# PIC32MX460F256L device description
Architecture: MIPS; Family: PIC32MX; Series: PIC32MX
Registers are 32-bit, read-write, no defined reset value unless marked. A register's access mark holds for its fields unless they carry their own. Offsets are from the block's base; [hi:lo] are bit positions; {n}, {i} and the like mark numbered series.

## PORT
Instances: PORT 0x1f886000 in periph2
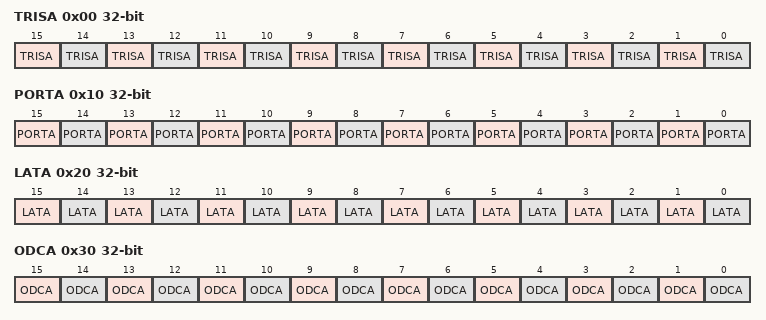
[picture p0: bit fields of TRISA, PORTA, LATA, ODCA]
0x00 TRISA
  [15] TRISA, [14] TRISA, [13] TRISA, [12] TRISA, [11] TRISA, [10] TRISA, [9] TRISA, [8] TRISA, [7] TRISA, [6] TRISA, [5] TRISA, [4] TRISA, [3] TRISA, [2] TRISA, [1] TRISA, [0] TRISA
0x10 PORTA
  [15] PORTA, [14] PORTA, [13] PORTA, [12] PORTA, [11] PORTA, [10] PORTA, [9] PORTA, [8] PORTA, [7] PORTA, [6] PORTA, [5] PORTA, [4] PORTA, [3] PORTA, [2] PORTA, [1] PORTA, [0] PORTA
0x20 LATA
  [15] LATA, [14] LATA, [13] LATA, [12] LATA, [11] LATA, [10] LATA, [9] LATA, [8] LATA, [7] LATA, [6] LATA, [5] LATA, [4] LATA, [3] LATA, [2] LATA, [1] LATA, [0] LATA
0x30 ODCA
  [15] ODCA, [14] ODCA, [13] ODCA, [12] ODCA, [11] ODCA, [10] ODCA, [9] ODCA, [8] ODCA, [7] ODCA, [6] ODCA, [5] ODCA, [4] ODCA, [3] ODCA, [2] ODCA, [1] ODCA, [0] ODCA
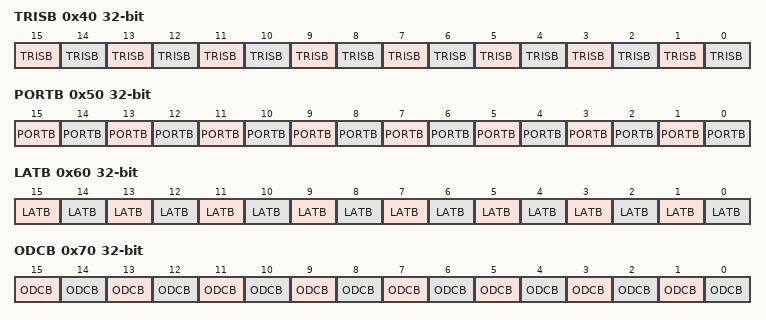
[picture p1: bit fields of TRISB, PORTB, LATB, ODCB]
0x40 TRISB
  [15] TRISB, [14] TRISB, [13] TRISB, [12] TRISB, [11] TRISB, [10] TRISB, [9] TRISB, [8] TRISB, [7] TRISB, [6] TRISB, [5] TRISB, [4] TRISB, [3] TRISB, [2] TRISB, [1] TRISB, [0] TRISB
0x50 PORTB
  [15] PORTB, [14] PORTB, [13] PORTB, [12] PORTB, [11] PORTB, [10] PORTB, [9] PORTB, [8] PORTB, [7] PORTB, [6] PORTB, [5] PORTB, [4] PORTB, [3] PORTB, [2] PORTB, [1] PORTB, [0] PORTB
0x60 LATB
  [15] LATB, [14] LATB, [13] LATB, [12] LATB, [11] LATB, [10] LATB, [9] LATB, [8] LATB, [7] LATB, [6] LATB, [5] LATB, [4] LATB, [3] LATB, [2] LATB, [1] LATB, [0] LATB
0x70 ODCB
  [15] ODCB, [14] ODCB, [13] ODCB, [12] ODCB, [11] ODCB, [10] ODCB, [9] ODCB, [8] ODCB, [7] ODCB, [6] ODCB, [5] ODCB, [4] ODCB, [3] ODCB, [2] ODCB, [1] ODCB, [0] ODCB
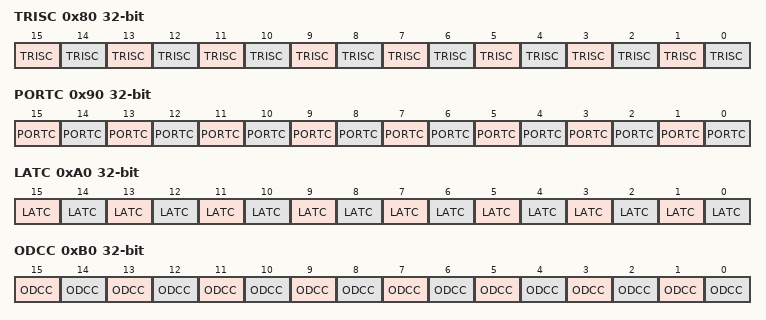
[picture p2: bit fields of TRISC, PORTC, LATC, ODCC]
0x80 TRISC
  [15] TRISC, [14] TRISC, [13] TRISC, [12] TRISC, [11] TRISC, [10] TRISC, [9] TRISC, [8] TRISC, [7] TRISC, [6] TRISC, [5] TRISC, [4] TRISC, [3] TRISC, [2] TRISC, [1] TRISC, [0] TRISC
0x90 PORTC
  [15] PORTC, [14] PORTC, [13] PORTC, [12] PORTC, [11] PORTC, [10] PORTC, [9] PORTC, [8] PORTC, [7] PORTC, [6] PORTC, [5] PORTC, [4] PORTC, [3] PORTC, [2] PORTC, [1] PORTC, [0] PORTC
0xA0 LATC
  [15] LATC, [14] LATC, [13] LATC, [12] LATC, [11] LATC, [10] LATC, [9] LATC, [8] LATC, [7] LATC, [6] LATC, [5] LATC, [4] LATC, [3] LATC, [2] LATC, [1] LATC, [0] LATC
0xB0 ODCC
  [15] ODCC, [14] ODCC, [13] ODCC, [12] ODCC, [11] ODCC, [10] ODCC, [9] ODCC, [8] ODCC, [7] ODCC, [6] ODCC, [5] ODCC, [4] ODCC, [3] ODCC, [2] ODCC, [1] ODCC, [0] ODCC
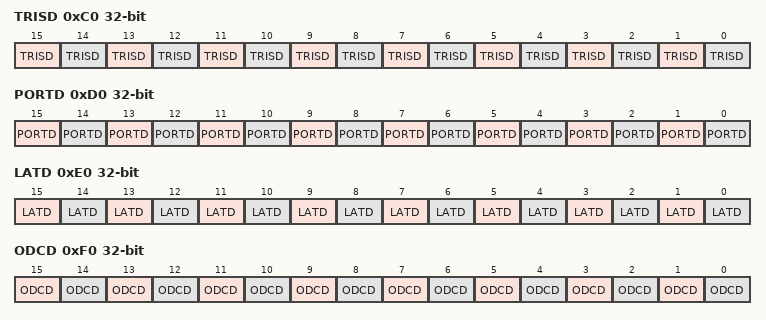
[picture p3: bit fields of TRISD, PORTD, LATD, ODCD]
0xC0 TRISD
  [15] TRISD, [14] TRISD, [13] TRISD, [12] TRISD, [11] TRISD, [10] TRISD, [9] TRISD, [8] TRISD, [7] TRISD, [6] TRISD, [5] TRISD, [4] TRISD, [3] TRISD, [2] TRISD, [1] TRISD, [0] TRISD
0xD0 PORTD
  [15] PORTD, [14] PORTD, [13] PORTD, [12] PORTD, [11] PORTD, [10] PORTD, [9] PORTD, [8] PORTD, [7] PORTD, [6] PORTD, [5] PORTD, [4] PORTD, [3] PORTD, [2] PORTD, [1] PORTD, [0] PORTD
0xE0 LATD
  [15] LATD, [14] LATD, [13] LATD, [12] LATD, [11] LATD, [10] LATD, [9] LATD, [8] LATD, [7] LATD, [6] LATD, [5] LATD, [4] LATD, [3] LATD, [2] LATD, [1] LATD, [0] LATD
0xF0 ODCD
  [15] ODCD, [14] ODCD, [13] ODCD, [12] ODCD, [11] ODCD, [10] ODCD, [9] ODCD, [8] ODCD, [7] ODCD, [6] ODCD, [5] ODCD, [4] ODCD, [3] ODCD, [2] ODCD, [1] ODCD, [0] ODCD
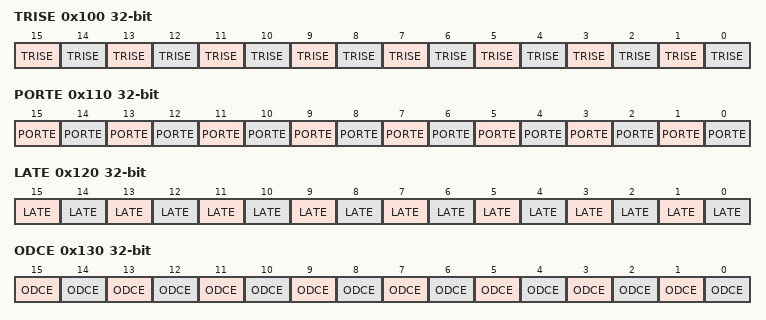
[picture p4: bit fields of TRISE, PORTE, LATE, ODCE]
0x100 TRISE
  [15] TRISE, [14] TRISE, [13] TRISE, [12] TRISE, [11] TRISE, [10] TRISE, [9] TRISE, [8] TRISE, [7] TRISE, [6] TRISE, [5] TRISE, [4] TRISE, [3] TRISE, [2] TRISE, [1] TRISE, [0] TRISE
0x110 PORTE
  [15] PORTE, [14] PORTE, [13] PORTE, [12] PORTE, [11] PORTE, [10] PORTE, [9] PORTE, [8] PORTE, [7] PORTE, [6] PORTE, [5] PORTE, [4] PORTE, [3] PORTE, [2] PORTE, [1] PORTE, [0] PORTE
0x120 LATE
  [15] LATE, [14] LATE, [13] LATE, [12] LATE, [11] LATE, [10] LATE, [9] LATE, [8] LATE, [7] LATE, [6] LATE, [5] LATE, [4] LATE, [3] LATE, [2] LATE, [1] LATE, [0] LATE
0x130 ODCE
  [15] ODCE, [14] ODCE, [13] ODCE, [12] ODCE, [11] ODCE, [10] ODCE, [9] ODCE, [8] ODCE, [7] ODCE, [6] ODCE, [5] ODCE, [4] ODCE, [3] ODCE, [2] ODCE, [1] ODCE, [0] ODCE
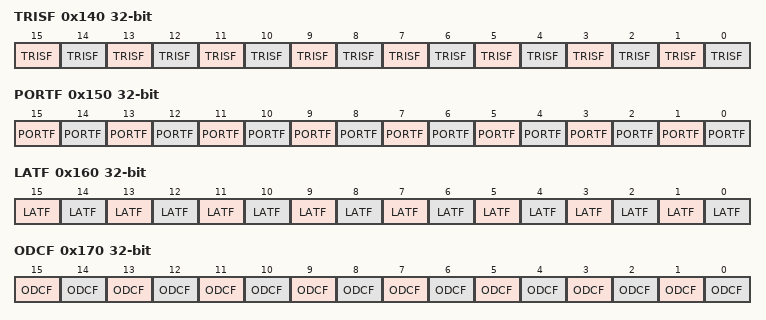
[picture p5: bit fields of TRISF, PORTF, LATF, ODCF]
0x140 TRISF
  [15] TRISF, [14] TRISF, [13] TRISF, [12] TRISF, [11] TRISF, [10] TRISF, [9] TRISF, [8] TRISF, [7] TRISF, [6] TRISF, [5] TRISF, [4] TRISF, [3] TRISF, [2] TRISF, [1] TRISF, [0] TRISF
0x150 PORTF
  [15] PORTF, [14] PORTF, [13] PORTF, [12] PORTF, [11] PORTF, [10] PORTF, [9] PORTF, [8] PORTF, [7] PORTF, [6] PORTF, [5] PORTF, [4] PORTF, [3] PORTF, [2] PORTF, [1] PORTF, [0] PORTF
0x160 LATF
  [15] LATF, [14] LATF, [13] LATF, [12] LATF, [11] LATF, [10] LATF, [9] LATF, [8] LATF, [7] LATF, [6] LATF, [5] LATF, [4] LATF, [3] LATF, [2] LATF, [1] LATF, [0] LATF
0x170 ODCF
  [15] ODCF, [14] ODCF, [13] ODCF, [12] ODCF, [11] ODCF, [10] ODCF, [9] ODCF, [8] ODCF, [7] ODCF, [6] ODCF, [5] ODCF, [4] ODCF, [3] ODCF, [2] ODCF, [1] ODCF, [0] ODCF
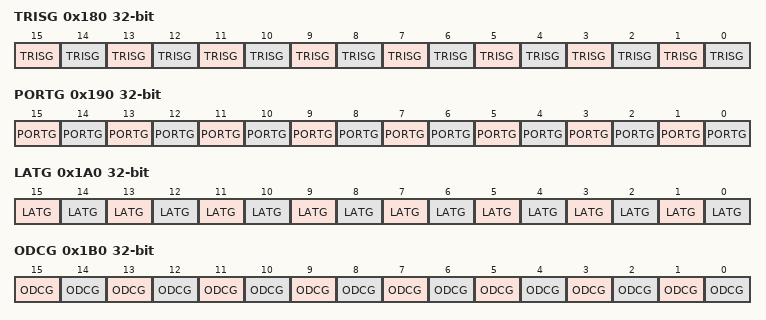
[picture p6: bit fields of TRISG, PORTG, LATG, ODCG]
0x180 TRISG
  [15] TRISG, [14] TRISG, [13] TRISG, [12] TRISG, [11] TRISG, [10] TRISG, [9] TRISG, [8] TRISG, [7] TRISG, [6] TRISG, [5] TRISG, [4] TRISG, [3] TRISG, [2] TRISG, [1] TRISG, [0] TRISG
0x190 PORTG
  [15] PORTG, [14] PORTG, [13] PORTG, [12] PORTG, [11] PORTG, [10] PORTG, [9] PORTG, [8] PORTG, [7] PORTG, [6] PORTG, [5] PORTG, [4] PORTG, [3] PORTG, [2] PORTG, [1] PORTG, [0] PORTG
0x1A0 LATG
  [15] LATG, [14] LATG, [13] LATG, [12] LATG, [11] LATG, [10] LATG, [9] LATG, [8] LATG, [7] LATG, [6] LATG, [5] LATG, [4] LATG, [3] LATG, [2] LATG, [1] LATG, [0] LATG
0x1B0 ODCG
  [15] ODCG, [14] ODCG, [13] ODCG, [12] ODCG, [11] ODCG, [10] ODCG, [9] ODCG, [8] ODCG, [7] ODCG, [6] ODCG, [5] ODCG, [4] ODCG, [3] ODCG, [2] ODCG, [1] ODCG, [0] ODCG
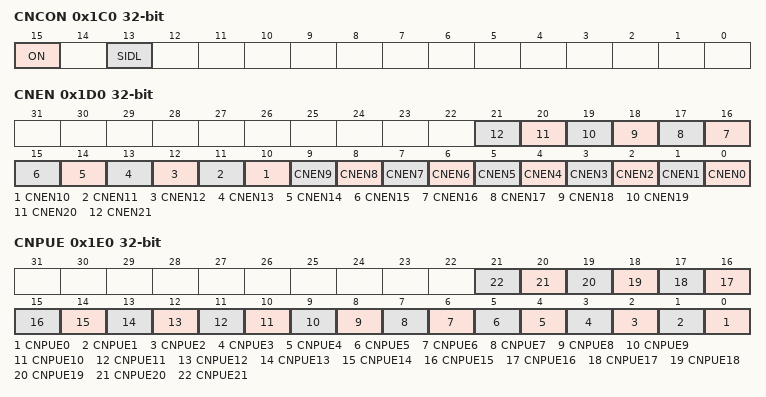
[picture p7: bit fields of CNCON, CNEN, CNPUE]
0x1C0 CNCON
  [15] ON, [13] SIDL
0x1D0 CNEN
  [n] CNEN{n} (n=0..21)
0x1E0 CNPUE
  [n] CNPUE{n} (n=0..21)

## Notices in the file
Copyright (c) 2019 Microchip Technology Inc.
SPDX-License-Identifier: Apache-2.0
Licensed under the Apache License, Version 2.0 (the "License");
you may not use this file except in compliance with the License.
You may obtain a copy of the License at
http://www.apache.org/licenses/LICENSE-2.0
Unless required by applicable law or agreed to in writing, software
distributed under the License is distributed on an "AS IS" BASIS,
WITHOUT WARRANTIES OR CONDITIONS OF ANY KIND, either express or implied.
See the License for the specific language governing permissions and
limitations under the License.
